# PIC16LF627 register map
Vendor: Microchip
Architecture 16xxxx. Special function registers and configuration words.
Registers are 8-bit, read-write, no defined reset value unless marked. A register's access mark holds for its fields unless they carry their own. Addresses are absolute, and some are shared; only a register's first bit layout is shown; lines under a group give offsets from that group; [hi:lo] are bit positions; {n}, {i} and the like mark numbered series; 'fields as' and 'values as' point back to an identical list; <NAME> marks a mode.

## Further device data
pins=1: RA2/AN2/Vref; 2: RA3/AN3/CMP1; 3: RA4/T0CKI/CMP2; 4: RA5/MCLR/Vpp; 5: Vss; 6: RB0/INT; 7: RB1/RX/DT; 8: RB2/TX/CK; 9: RB3/CCP1; 10: RB4/PGM; 11: RB5; 12: RB6/T1OSO/T1CKI/PGC; 13: RB7/T1OSI/PGD; 14: Vdd; 15: RA6/OSC2/CLKOUT; 16: RA7/OSC1/CLKIN; 17: RA0/AN0; 18: RA1/AN1

## SFR
0x00 INDF access not given
0x01 TMR0 — (power-on value xxxxxxxx)
0x02 PCL reset 0x0
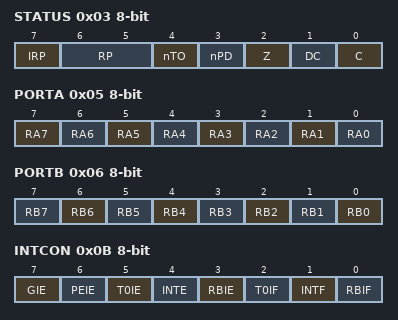
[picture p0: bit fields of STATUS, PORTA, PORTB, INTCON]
0x03 STATUS — (power-on value 00011xxx)
  [7] IRP, [6:5] RP, [4] nTO ro, [3] nPD ro, [2] Z, [1] DC, [0] C
0x04 FSR — (power-on value xxxxxxxx)
0x05 PORTA — (power-on value xxxx0000)
  [7] RA7, [6] RA6, [5] RA5 ro, [n] RA{n} (n=0..4)
0x06 PORTB — (power-on value xxxxxxxx)
  [n] RB{n} (n=0..7)
0x0A PCLATH reset 0x0
  [4:0] PCLATH
0x0B INTCON — (power-on value 0000000x)
  [7] GIE, [6] PEIE, [5] T0IE, [4] INTE, [3] RBIE, [2] T0IF, [1] INTF, [0] RBIF
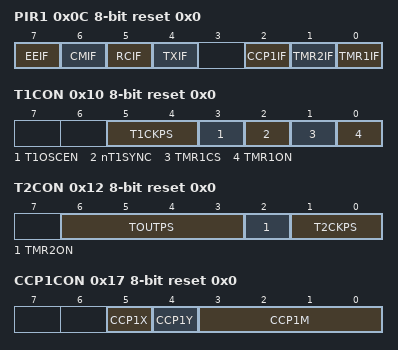
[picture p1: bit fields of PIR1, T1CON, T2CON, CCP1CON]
0x0C PIR1 reset 0x0
  [7] EEIF, [6] CMIF, [5] RCIF ro, [4] TXIF ro, [2] CCP1IF, [1] TMR2IF, [0] TMR1IF
0x0E TMR1L — (power-on value xxxxxxxx)
0x0F TMR1H — (power-on value xxxxxxxx)
0x10 T1CON reset 0x0
  [5:4] T1CKPS, [3] T1OSCEN, [2] nT1SYNC, [1] TMR1CS, [0] TMR1ON
0x11 TMR2 reset 0x0
0x12 T2CON reset 0x0
  [6:3] TOUTPS, [2] TMR2ON, [1:0] T2CKPS
0x15 CCPR1L — (power-on value xxxxxxxx)
0x16 CCPR1H — (power-on value xxxxxxxx)
0x17 CCP1CON reset 0x0
  [5] CCP1X, [4] CCP1Y, [3:0] CCP1M
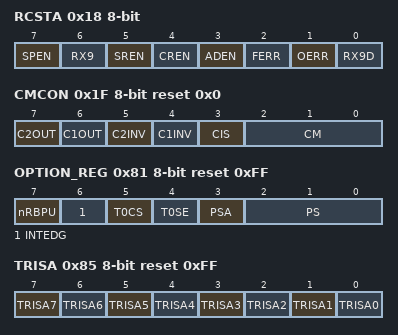
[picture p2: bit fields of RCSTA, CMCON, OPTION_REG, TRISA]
0x18 RCSTA — (power-on value 0000000x)
  [7] SPEN, [6] RX9, [5] SREN, [4] CREN, [3] ADEN, [2] FERR ro, [1] OERR ro, [0] RX9D ro
0x19 TXREG reset 0x0
0x1A RCREG ro reset 0x0
0x1F CMCON reset 0x0
  [7] C2OUT ro, [6] C1OUT ro, [5] C2INV, [4] C1INV, [3] CIS, [2:0] CM
0x81 OPTION_REG reset 0xFF
  [7] nRBPU, [6] INTEDG, [5] T0CS, [4] T0SE, [3] PSA, [2:0] PS
0x85 TRISA reset 0xFF
  [7] TRISA7, [6] TRISA6, [5] TRISA5 ro, [n] TRISA{n} (n=0..4)
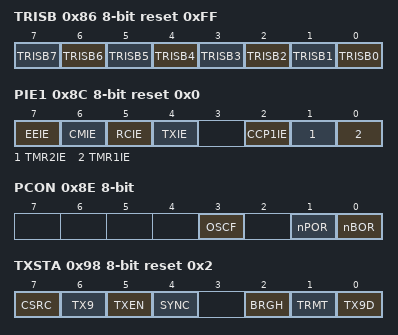
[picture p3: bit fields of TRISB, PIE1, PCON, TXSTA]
0x86 TRISB reset 0xFF
  [n] TRISB{n} (n=0..7)
0x8C PIE1 reset 0x0
  [7] EEIE, [6] CMIE, [5] RCIE, [4] TXIE, [2] CCP1IE, [1] TMR2IE, [0] TMR1IE
0x8E PCON — (power-on value ----1-0x)
  [3] OSCF, [1] nPOR, [0] nBOR
0x92 PR2 reset 0xFF
0x98 TXSTA reset 0x2
  [7] CSRC, [6] TX9, [5] TXEN, [4] SYNC, [2] BRGH, [1] TRMT ro, [0] TX9D
0x99 SPBRG reset 0x0
0x9A EEDATA — (power-on value xxxxxxxx)
0x9B EEADR — (power-on value xxxxxxxx)
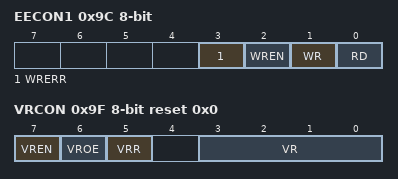
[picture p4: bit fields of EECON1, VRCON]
0x9C EECON1 — (power-on value ----x000)
  [3] WRERR
  [2] WREN
  [1] WR — (can only be set)
  [0] RD — (can only be set)
0x9D EECON2 wo
0x9F VRCON reset 0x0
  [7] VREN, [6] VROE, [5] VRR, [3:0] VR

## CONFIG — Configuration words, addresses in ProgramSpace
0x2007 CONFIG 14-bit reset 0x3FFF
  [13:10] CP — Code Protection bits
    15=OFF (Program memory code protection off); 10=Program memory code protection off; 5=0200h-03FFh code protected; 0=ALL (0000h-03FFh code protected)
  [8] CPD — Data Code Protection bit
    1=OFF (Data memory code protection off); 0=ON (Data memory code protected)
  [7] LVP — Low-Voltage Programming Enable bit
    1=ON (RB4/PGM pin has PGM function, low-voltage programming enabled); 0=OFF (RB4/PGM pin has digital I/O function, HV on MCLR must be used for programming)
  [6] BOREN — Brown-out Reset Enable bit
    1=ON (BOD Reset enabled); 0=OFF (BOD Reset disabled)
  [5] MCLRE — RA5/MCLR pin function select
    1=ON (RA5/MCLR pin function is MCLR); 0=OFF (RA5/MCLR pin function is digital input, MCLR internally tied to VDD)
  [3] PWRTE — Power-up Timer Enable bit
    1=OFF (PWRT disabled); 0=ON (PWRT enabled)
  [2] WDTE — Watchdog Timer Enable bit
    1=ON (WDT enabled); 0=OFF (WDT disabled)
  [4:0] FOSC — Oscillator Selection bits
    0b1xx11=ERCLK (ER oscillator: CLKOUT function on RA6/OSC2/CLKOUT pin, Resistor on RA7/OSC1/CLKIN); 0b1xx10=ERIO (ER oscillator: I/O function on RA6/OSC2/CLKOUT pin, Resistor on RA7/OSC1/CLKIN); 0b1xx01=INTOSCCLK (INTRC oscillator: CLKOUT function on RA6/OSC2/CLKOUT pin, I/O function on RA7/OSC1/CLKIN); 0b1xx00=INTOSCIO (INTRC oscillator: I/O function on RA6/OSC2/CLKOUT pin, I/O function on RA7/OSC1/CLKIN); 0b0xx11=ECIO (EC: I/O function on RA6/OSC2/CLKOUT pin, CLKIN on RA7/OSC1/CLKIN); 0b0xx10=HS (HS oscillator: High-speed crystal/resonator on RA6/OSC2/CLKOUT and RA7/OSC1/CLKIN); 0b0xx01=XT (XT oscillator: Crystal/resonator on RA6/OSC2/CLKOUT and RA7/OSC1/CLKIN); 0b0xx00=LP (LP oscillator: Low-power crystal on RA6/OSC2/CLKOUT and RA7/OSC1/CLKIN)
